AUTOSAR XML (schema 4-2-1)
package /ComponentTypes
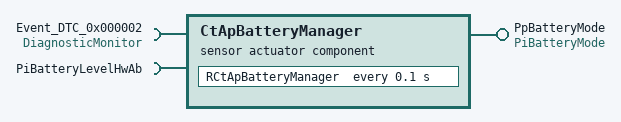
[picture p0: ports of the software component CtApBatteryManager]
  sensor actuator sw component type CtApBatteryManager
    provide port PpBatteryMode: mode-switch-sender-com-spec{enhanced-mode-api=false, mode-group=BatteryMode, queue-length=1}, provided-interface=PiBatteryMode
    require port Event_DTC_0x000002: required-interface=DiagnosticMonitor
    require port PiBatteryLevelHwAb: required-interface=PiBatteryLevelHwAb
    behavior CtApBatteryManager_InternalBehavior
      timing event TMT_RCtApBatteryManager: start-on-event=RCtApBatteryManager, period=0.1
      runnable RCtApBatteryManager
        mode switch point SWITCH_PpBatteryMode_BatteryMode: mode-group=PpBatteryMode.BatteryMode
        sync call SC_Event_DTC_0x000002_SetEventStatus: operation=Event_DTC_0x000002.SetEventStatus, timeout=0
        sync call SC_PiBatteryLevelHwAb_ReadChannel: operation=PiBatteryLevelHwAb.ReadChannel, timeout=0
  swc implementation CtApBatteryManager_Implementation: behavior=CtApBatteryManager_InternalBehavior
    code-descriptors:
      code Default: artifact-descriptors=autosar-engineering-object={short-label=Default, category=SWSRC}
